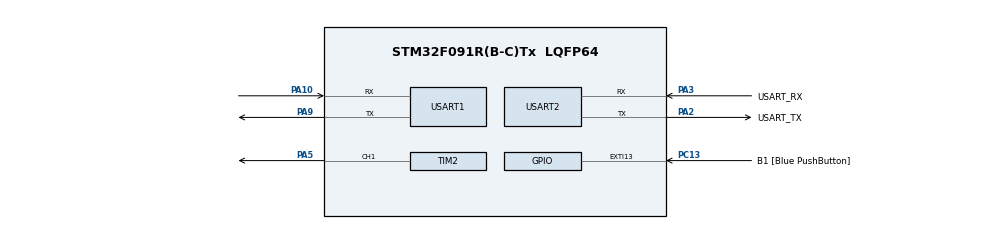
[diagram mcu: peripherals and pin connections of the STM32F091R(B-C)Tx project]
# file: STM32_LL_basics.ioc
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Mcu.Family=STM32F0
Mcu.Name=STM32F091R(B-C)Tx
Mcu.Package=LQFP64
NVIC.EXTI4_15_IRQn=true\:0\:0\:false\:false\:true\:true\:true\:true
NVIC.TIM2_IRQn=true\:0\:0\:false\:false\:true\:true\:true\:true
NVIC.TIM6_DAC_IRQn=true\:0\:0\:false\:false\:true\:true\:true\:true
NVIC.USART1_IRQn=true\:0\:0\:false\:false\:true\:true\:true\:true
NVIC.USART2_IRQn=true\:0\:0\:false\:false\:true\:true\:true\:true
PA10.Mode=Asynchronous
PA10.Signal=USART1_RX
PA13.GPIO_Label=TMS
PA13.Mode=Serial_Wire
PA13.Signal=SYS_SWDIO
PA14.GPIO_Label=TCK
PA14.Mode=Serial_Wire
PA14.Signal=SYS_SWCLK
PA2.GPIO_Label=USART_TX
PA2.GPIO_Mode=GPIO_MODE_AF_PP
PA2.GPIO_PuPd=GPIO_NOPULL
PA2.GPIO_Speed=GPIO_SPEED_FREQ_LOW
PA2.Mode=Asynchronous
PA2.Signal=USART2_TX
PA3.GPIO_Label=USART_RX
PA3.GPIO_Mode=GPIO_MODE_AF_PP
PA3.GPIO_PuPd=GPIO_NOPULL
PA3.GPIO_Speed=GPIO_SPEED_FREQ_LOW
PA3.Mode=Asynchronous
PA3.Signal=USART2_RX
PA5.Signal=S_TIM2_CH1_ETR
PA9.Mode=Asynchronous
PA9.Signal=USART1_TX
PC13.GPIO_Label=B1 [Blue PushButton]
PC13.GPIO_ModeDefaultEXTI=GPIO_MODE_IT_FALLING
PC13.Signal=GPXTI13
PC14OSC32_IN.Mode=LSE-External-Oscillator
PC14OSC32_IN.Signal=RCC_OSC32_IN
PC15OSC32_OUT.Mode=LSE-External-Oscillator
PC15OSC32_OUT.Signal=RCC_OSC32_OUT
PF0-OSC_IN.Mode=HSE-External-Clock-Source
PF0-OSC_IN.Signal=RCC_OSC_IN
PF1-OSC_OUT.Signal=RCC_OSC_OUT
ProjectManager.HeapSize=0x200
ProjectManager.StackSize=0x400
ProjectManager.TargetToolchain=STM32CubeIDE
RCC.AHBFreq_Value=48000000
RCC.APB1Freq_Value=48000000
RCC.APB1TimFreq_Value=48000000
RCC.FLatency-AdvancedSettings=FLASH_LATENCY_1
RCC.HCLKFreq_Value=48000000
RCC.PLLDivider=RCC_PREDIV_DIV2
RCC.PLLMUL=RCC_PLL_MUL12
RCC.PREFETCH_ENABLE-AdvancedSettings=1
RCC.SYSCLKFreq_VALUE=48000000
RCC.SYSCLKSource=RCC_SYSCLKSOURCE_PLLCLK
SH.S_TIM2_CH1_ETR.0=TIM2_CH1,PWM Generation1 CH1
TIM2.AutoReloadPreload=TIM_AUTORELOAD_PRELOAD_ENABLE
TIM2.Channel-PWM\ Generation1\ CH1=TIM_CHANNEL_1
TIM2.Period=1000
TIM2.Prescaler=48
TIM2.Pulse-PWM\ Generation1\ CH1=500
TIM6.AutoReloadPreload=TIM_AUTORELOAD_PRELOAD_ENABLE
TIM6.Period=1000
TIM6.Prescaler=48
USART1.VirtualMode-Asynchronous=VM_ASYNC
USART2.VirtualMode=VM_ASYNC
USART2.VirtualMode-Asynchronous=VM_ASYNC
VP_TIM6_VS_ClockSourceINT.Mode=Enable_Timer
board=NUCLEO-F091RC

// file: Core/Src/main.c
/* USER CODE BEGIN Header */
/**
  ******************************************************************************
  * @file           : main.c
  * @brief          : Main program body
  ******************************************************************************
  * @attention
  *
  * Copyright (c) 2023 STMicroelectronics.
  * All rights reserved.
  *
  * This software is licensed under terms that can be found in the LICENSE file
  * in the root directory of this software component.
  * If no LICENSE file comes with this software, it is provided AS-IS.
  *
  ******************************************************************************
  */
/* USER CODE END Header */
#include "main.h"
#include "tim.h"
#include "usart.h"
#include "gpio.h"

/* USER CODE BEGIN Includes */
#include <stdio.h>
/* USER CODE END Includes */

void SystemClock_Config(void);

int main(void)
{

  /* MCU Configuration--------------------------------------------------------*/

  /* Reset of all peripherals, Initializes the Flash interface and the Systick. */
  LL_APB1_GRP2_EnableClock(LL_APB1_GRP2_PERIPH_SYSCFG);
  LL_APB1_GRP1_EnableClock(LL_APB1_GRP1_PERIPH_PWR);

  /* Configure the system clock */
  SystemClock_Config();

  /* Initialize all configured peripherals */
  MX_GPIO_Init();
  MX_TIM2_Init();
  MX_TIM6_Init();
  MX_USART1_UART_Init();
  MX_USART2_UART_Init();
  /* USER CODE BEGIN 2 */
  uart_init();
  tim_init();
  gpio_init();
  /* USER CODE END 2 */

  /* Infinite loop */
  /* USER CODE BEGIN WHILE */
  printf("===== This is LL basic =====\r\n");
  uint16_t time_delay = 0;
  while (1)
  {
	  uart_idle();
    /* USER CODE END WHILE */
    /* USER CODE BEGIN 3 */
    printf("time %d s \r\n", time_delay++);
    tim_delay_ms(1000);
  }
  /* USER CODE END 3 */
}

void SystemClock_Config(void)
{
  LL_FLASH_SetLatency(LL_FLASH_LATENCY_1);
  while(LL_FLASH_GetLatency() != LL_FLASH_LATENCY_1)
  {
  }
  LL_RCC_HSI_Enable();

   /* Wait till HSI is ready */
  while(LL_RCC_HSI_IsReady() != 1)
  {

  }
  LL_RCC_HSI_SetCalibTrimming(16);
  LL_RCC_PLL_ConfigDomain_SYS(LL_RCC_PLLSOURCE_HSI, LL_RCC_PLL_MUL_12, LL_RCC_PREDIV_DIV_2);
  LL_RCC_PLL_Enable();

   /* Wait till PLL is ready */
  while(LL_RCC_PLL_IsReady() != 1)
  {

  }
  LL_RCC_SetAHBPrescaler(LL_RCC_SYSCLK_DIV_1);
  LL_RCC_SetAPB1Prescaler(LL_RCC_APB1_DIV_1);
  LL_RCC_SetSysClkSource(LL_RCC_SYS_CLKSOURCE_PLL);

   /* Wait till System clock is ready */
  while(LL_RCC_GetSysClkSource() != LL_RCC_SYS_CLKSOURCE_STATUS_PLL)
  {

  }
  LL_Init1msTick(48000000);
  LL_SetSystemCoreClock(48000000);
  LL_RCC_SetUSARTClockSource(LL_RCC_USART1_CLKSOURCE_PCLK1);
  LL_RCC_SetUSARTClockSource(LL_RCC_USART2_CLKSOURCE_PCLK1);
}

void Error_Handler(void)
{
  __disable_irq();
  while (1)
  {
  }
}
